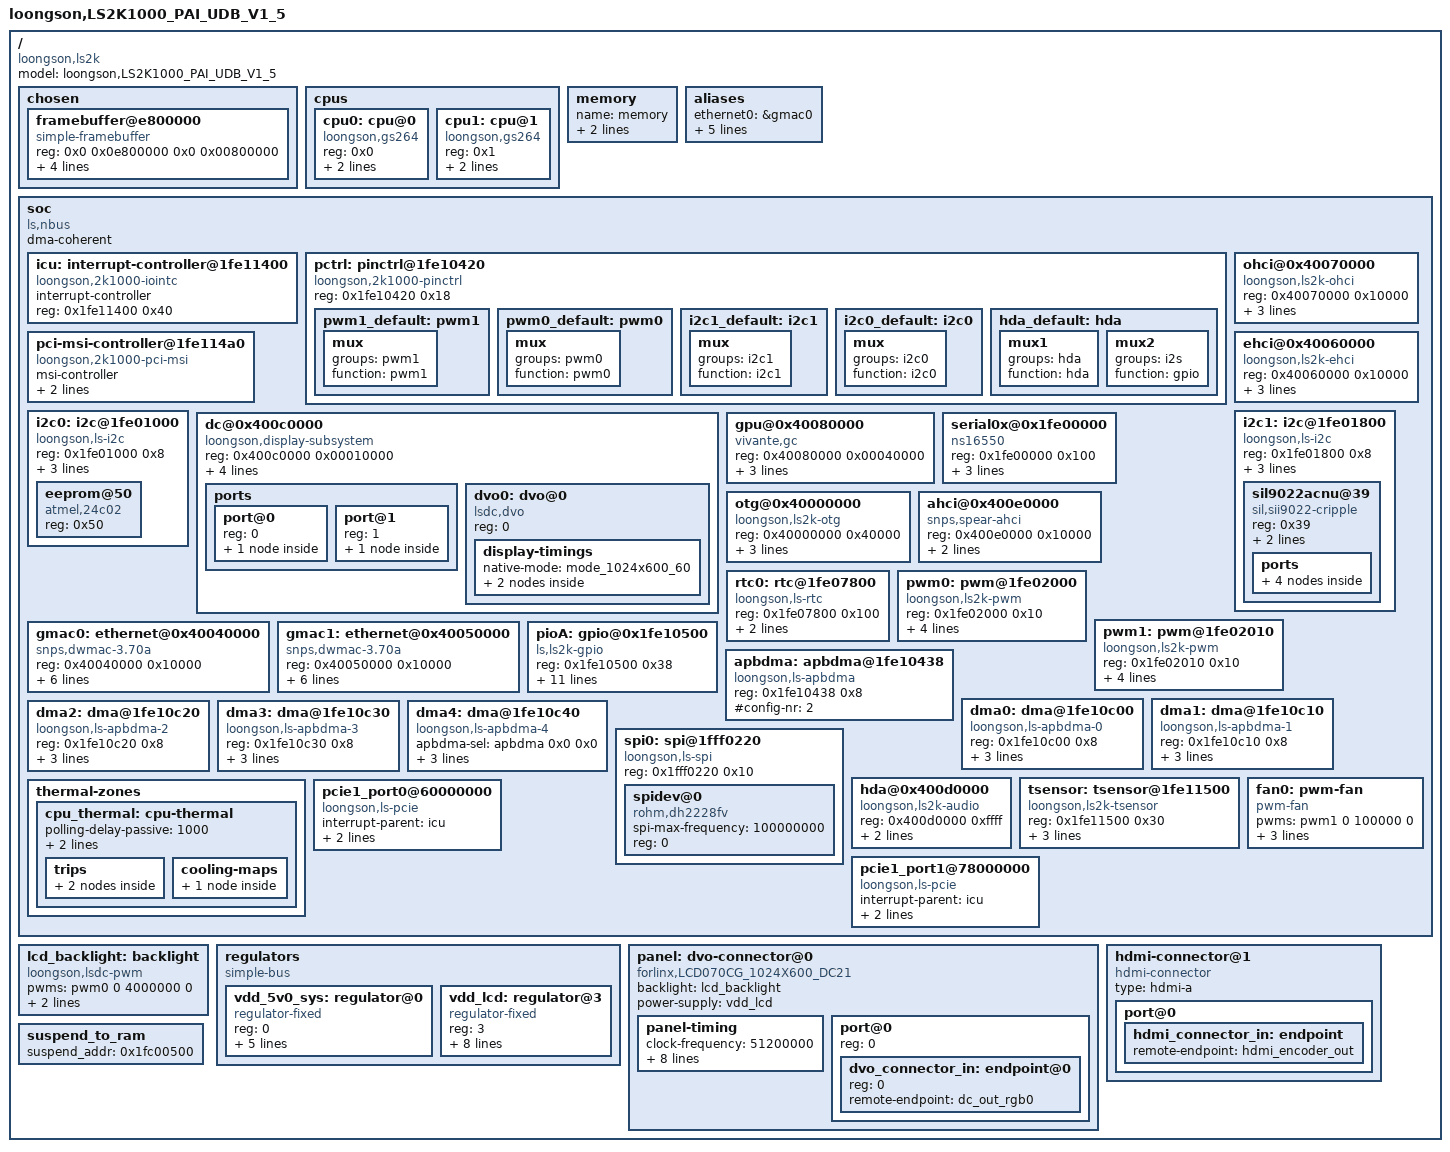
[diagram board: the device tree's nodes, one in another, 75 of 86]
/*
 * 2K1000 Device Tree Source for LS2K1000 boards
 */

#include <dt-bindings/thermal/thermal.h>
#include <dt-bindings/gpio/gpio.h>
#include <dt-bindings/pwm/pwm.h>

/dts-v1/;
/ {
	model = "loongson,LS2K1000_PAI_UDB_V1_5";
	compatible = "loongson,ls2k";
	#address-cells = <2>;
	#size-cells = <2>;

	/* This enables graphical output via bootloader-enabled display */
	chosen {
		// bootargs = "console=ttyS0,115200 root=/dev/sda1";

		#address-cells = <2>;
		#size-cells = <2>;
		ranges;

		framebuffer@e800000 {
			status= "okay";
			compatible = "simple-framebuffer";
			reg = <0x0 0x0e800000 0x0 0x00800000>;
			width = <1024>;
			height = <600>;
			stride = <(1024 * 2)>;
			format = "r5g6b5";
		};

		/*
		framebuffer@e800000 {
			status= "okay";
			compatible = "simple-framebuffer";
			reg = <0x0 0x0e800000 0x0 0x00800000>;
			width = <800>;
			height = <480>;
			stride = <(800 * 2)>;
			format = "r5g6b5";
		};
		*/
	};

	cpus {
		#address-cells = <1>;
		#size-cells = <0>;

		cpu0: cpu@0 {
			device_type = "cpu";
			compatible = "loongson,gs264";
			reg = <0x0>;
			loongson,dvfs-vid-points = <
				/* Node:kHz  DVFS:vid[0:5] */
				266666  0x11
				320000  0x10
				400000  0x01
				533333  0x00
				800000  0x00
				>;
		};

		cpu1: cpu@1 {
			device_type = "cpu";
			compatible = "loongson,gs264";
			reg = <0x1>;
			loongson,dvfs-vid-points = <
				/* Node:kHz  DVFS:vid[0:5] */
				266666  0x11
				320000  0x10
				400000  0x01
				533333  0x11
				800000  0x11
				>;
		};
	};

	// ls2k1000 pai board have only 2GB on-board RAM
	memory {
		name = "memory";
		device_type = "memory";
		// 238 MB at 2 MB
		// 496 MB at 512 MB
		// 1280 MB at 4352 MB
		// total 2014 MB
		reg = <0x00000000 0x00200000 0x00000000 0x0ee00000
		       0x00000000 0x20000000 0x00000000 0x1f000000
		       0x00000000 0x90000000 0x00000000 0x50000000>;
	};

	aliases {
		ethernet0 = &gmac0;
		ethernet1 = &gmac1;
		i2c0 = &i2c0;
		i2c1 = &i2c1;
		pwm0 = &pwm0;
		pwm1 = &pwm1;
	};
	// all soc device use 32bit address

	soc {
		compatible = "ls,nbus", "simple-bus";
		#address-cells = <1>;
		#size-cells = <1>;
		ranges = <0x10000000 0 0x10000000 0x10000000
			  0x40000000 0 0x40000000 0x40000000
			  0x20000000 0 0x20000000 0x20000000
			  0x0d000000 0 0x0d000000 0x02000000>;

		dma-coherent;

		icu: interrupt-controller@1fe11400 {
			compatible = "loongson,2k1000-iointc";
			interrupt-controller;
			#interrupt-cells = <1>;
			reg = <0x1fe11400 0x40>;
		};

		pctrl:pinctrl@1fe10420 {
			compatible = "loongson,2k1000-pinctrl";
			reg = <0x1fe10420 0x18>;

			pwm1_default:pwm1 {
				mux {
					groups ="pwm1";
					function ="pwm1";
				};
			};

			pwm0_default:pwm0 {
				mux {
					groups ="pwm0";
					function ="pwm0";
				};
			};

			i2c1_default:i2c1 {
				mux {
					groups ="i2c1";
					function ="i2c1";
				};
			};

			i2c0_default:i2c0 {
				mux {
					groups ="i2c0";
					function ="i2c0";
				};
			};

			hda_default:hda {
				mux1 {
					groups ="hda";
					function ="hda";
				};

				mux2 {
					groups ="i2s";
					function ="gpio";
				};
			};
		};

		pci-msi-controller@1fe114a0 {
			compatible = "loongson,2k1000-pci-msi";
			msi-controller;
			msi-mask = <0xc0 0x40000c00>;
			reg = <0x1fe114a0 0x60>;
		};

		ohci@0x40070000 {
			compatible = "loongson,ls2k-ohci", "usb-ohci";
			reg = <0x40070000 0x10000>;
			interrupt-parent = <&icu>;
			interrupts = <59>;
			dma-mask = <0x0 0xffffffff>;
		};

		ehci@0x40060000 {
			compatible = "loongson,ls2k-ehci", "usb-ehci";
			reg = <0x40060000 0x10000>;
			interrupt-parent = <&icu>;
			interrupts = <58>;
			dma-mask = <0xffffffff 0xffffffff>;
		};

		i2c0: i2c@1fe01000 {
			compatible = "loongson,ls-i2c";
			reg = <0x1fe01000 0x8>;
			interrupt-parent = <&icu>;
			interrupts = <30>;

			pinctrl-0 = <&i2c0_default>;
			pinctrl-names = "default";

			#address-cells = <1>;
			#size-cells = <0>;

			eeprom@50 {
				compatible = "atmel,24c02";
				reg = <0x50>;
			};
		};

		i2c1: i2c@1fe01800 {
			compatible = "loongson,ls-i2c";
			reg = <0x1fe01800 0x8>;
			interrupt-parent = <&icu>;
			interrupts = <31>;

			#address-cells = <1>;
			#size-cells = <0>;

			pinctrl-0 = <&i2c1_default>;
			pinctrl-names = "default";

			sil9022acnu@39 {
				compatible = "sil,sii9022-cripple";
				/* Transmitter Programming Interface (TPI) address: 0x72 */
				reg = <0x39>;

				hpd-gpios = <&pioA 0 GPIO_ACTIVE_HIGH>;
				/* reset-gpios = <&pioA 39 GPIO_ACTIVE_LOW>; */
				interrupt-parent = <&pioA>;

				status = "okay";

				ports {
					#address-cells = <1>;
					#size-cells = <0>;

					port@0 {
						reg = <0>;

						hdmi_encoder_in: endpoint {
							remote-endpoint = <&dc_out_rgb1>;
						};
					};

					port@1 {
						reg = <1>;

						hdmi_encoder_out: endpoint {
							remote-endpoint = <&hdmi_connector_in>;
						};
					};
				};
			};

		};

		dc@0x400c0000 {
			compatible = "loongson,display-subsystem";
			reg = <0x400c0000 0x00010000>;
			interrupt-parent = <&icu>;
			interrupts = <36>;
			dma-mask = <0x00000000 0xffffffff>;

			output-ports = <&dvo0>;

			#address-cells = <1>;
			#size-cells = <0>;

			ports {
				#address-cells = <1>;
				#size-cells = <0>;

				port@0 {
					reg = <0>;
					dc_out_rgb0: endpoint {
						remote-endpoint = <&dvo_connector_in>;
					};
				};

				port@1 {
					reg = <1>;
					dc_out_rgb1: endpoint {
						remote-endpoint = <&hdmi_encoder_in>;
					};
				};
			};

			dvo0: dvo@0 {
				compatible = "lsdc,dvo";
				/* 0 for connector 0 (DVO0) */
				reg = <0>;

				display-timings {
					native-mode = <&mode_1024x600_60>;

					mode_1024x600_60: display-timing@0 {
						clock-frequency = <51200000>;
						hactive = <1024>;
						vactive = <600>;
						hsync-len = <4>;
						hfront-porch = <160>;
						hback-porch = <156>;
						vfront-porch = <11>;
						vback-porch = <23>;
						vsync-len = <1>;
					};

					mode_800x480_60: display-timing@1 {
						clock-frequency = <30066000>;
						hactive = <800>;
						vactive = <480>;
						hfront-porch = <50>;
						hback-porch = <70>;
						hsync-len = <50>;
						vback-porch = <0>;
						vfront-porch = <0>;
						vsync-len = <50>;
					};
				};
			};

		};

		gpu@0x40080000 {
			compatible = "vivante,gc";
			reg = <0x40080000 0x00040000>;
			interrupt-parent = <&icu>;
			interrupts = <37>;
			dma-mask = <0x00000000 0xffffffff>;
		};

		serial0x@0x1fe00000{
			device_type = "serial";
			compatible = "ns16550";
			reg = <0x1fe00000 0x100>;
			clock-frequency = <125000000>;
			interrupt-parent = <&icu>;
			interrupts = <8>;
		};

		otg@0x40000000 {
			compatible = "loongson,ls2k-otg";
			reg = <0x40000000 0x40000>;
			interrupt-parent = <&icu>;
			interrupts = <57>;
			dma-mask = <0x0 0xffffffff>;
		};

		ahci@0x400e0000{
			compatible = "snps,spear-ahci";
			reg = <0x400e0000 0x10000>;
			interrupt-parent = <&icu>;
			interrupts = <27>;
		};

		rtc0: rtc@1fe07800{
			compatible = "loongson,ls-rtc";
			reg = <0x1fe07800 0x100>;
			interrupt-parent = <&icu>;
			interrupts = <60>;
		};

		pwm0: pwm@1fe02000 {
			compatible = "loongson,ls2k-pwm";
			reg = <0x1fe02000 0x10>;
			clock-frequency = <125000000>;
			interrupt-parent = <&icu>;
			interrupts = <32>;
			#pwm-cells = <3>;
			pinctrl-0 = <&pwm0_default>;
			pinctrl-names = "default";
		};

		pwm1: pwm@1fe02010 {
			compatible = "loongson,ls2k-pwm";
			reg = <0x1fe02010 0x10>;
			clock-frequency = <125000000>;
			interrupt-parent = <&icu>;
			interrupts = <33>;
			#pwm-cells = <3>;
			pinctrl-0 = <&pwm1_default>;
			pinctrl-names = "default";
		};

		/* PWM controller nodes:
		 * If you want to use the "PWM" function,enable the "PWM"
		 * controller by configure general configuration register 0.
		 */
		/*
		pwm2: pwm@1fe02020{
			compatible = "loongson,ls2k-pwm";
			reg = <0x1fe02020 0x10>;
			clock-frequency = <125000000>;
			interrupt-parent = <&icu>;
			interrupts = <34>;
			#pwm-cells = <2>;
		};

		pwm3: pwm@1fe02030{
			compatible = "loongson,ls2k-pwm";
			reg = <0x1fe02030 0x10>;
			clock-frequency = <125000000>;
			interrupt-parent = <&icu>;
			interrupts = <35>;
			#pwm-cells = <2>;
		};*/

		gmac0: ethernet@0x40040000 {
			compatible = "snps,dwmac-3.70a", "ls,ls-gmac";
			reg = <0x40040000 0x10000>;
			interrupt-parent = <&icu>;
			interrupts = <20 21>;
			interrupt-names = "macirq", "eth_wake_irq";
			/* mac-address = [ 64 48 48 48 48 60  ]; */
			phy-mode = "rgmii";
			bus_id = <0x0>;
			phy_addr = <0xffffffff>;
			dma-mask = <0xffffffff 0xffffffff>;
		};

		gmac1: ethernet@0x40050000 {
			compatible = "snps,dwmac-3.70a", "ls,ls-gmac";
			reg = <0x40050000 0x10000>;
			interrupt-parent = <&icu>;
			interrupts = <22 23>;
			interrupt-names = "macirq", "eth_wake_irq";
			/* mac-address = [ 64 48 48 48 48 61  ]; */
			phy-mode = "rgmii";
			bus_id = <0x1>;
			phy_addr = <0xffffffff>;
			dma-mask = <0xffffffff 0xffffffff>;
		};

		pioA: gpio@0x1fe10500 {
			compatible = "ls,ls2k-gpio", "ls,ls-gpio";
			reg = <0x1fe10500 0x38>;
			ngpios = <64>;
			gpio-controller;
			#gpio-cells = <2>;
			gpio-ranges = <&pctrl 0 0 15>,
				      <&pctrl 16 16 15>,
				      <&pctrl 32 32 10>,
				      <&pctrl 44 44 20>;
			interrupt-parent = <&icu>;
			interrupts =
				<68>, <69>, <70>, <71>, <66>, <66>,
				<66>, <66>, <66>, <66>, <66>, <66>,
				<66>, <66>, <66>, <>,   <66>, <66>,
				<66>, <66>, <66>, <66>, <66>, <66>,
				<66>, <66>, <66>, <66>, <66>, <66>,
				<66>, <66>, <67>, <67>, <67>, <67>,
				<67>, <>,   <67>, <67>, <67>, <67>,
				<>,   <>,   <67>, <67>, <67>, <67>,
				<67>, <67>, <67>, <67>, <67>, <67>,
				<67>, <67>, <67>, <67>, <67>, <67>,
				<67>, <67>, <67>, <67>;
		};

		/* APB DMA controller nodes:
		 * apbdma node specify the commom property for dma node.
		 * the #config-nr must be 2,Used to provide APB sel region
		 * and APB DMA controler information.
		 */
		apbdma: apbdma@1fe10438{
			compatible = "loongson,ls-apbdma";
			reg = <0x1fe10438 0x8>;
			#config-nr = <2>;
		};
		/* DMA node should specify the apbdma-sel property using a
		 * phandle to the controller followed by number of APB sel
		 * region(max 9) and number of APB DMA controller(max 4).
		*/
		dma0: dma@1fe10c00 {
			compatible = "loongson,ls-apbdma-0";
			reg = <0x1fe10c00 0x8>;
			apbdma-sel = <&apbdma 0x0 0x0>;
			#dma-cells = <1>;
			dma-channels = <1>;
			dma-requests = <1>;
		};
		dma1: dma@1fe10c10 {
			compatible = "loongson,ls-apbdma-1";
			reg = <0x1fe10c10 0x8>;
			apbdma-sel = <&apbdma 0x5 0x1>;
			#dma-cells = <1>;
			dma-channels = <1>;
			dma-requests = <1>;
		};
		dma2: dma@1fe10c20 {
			compatible = "loongson,ls-apbdma-2";
			reg = <0x1fe10c20 0x8>;
			apbdma-sel = <&apbdma 0x6 0x2>;
			#dma-cells = <1>;
			dma-channels = <1>;
			dma-requests = <1>;
		};
		dma3: dma@1fe10c30 {
			compatible = "loongson,ls-apbdma-3";
			reg = <0x1fe10c30 0x8>;
			apbdma-sel = <&apbdma 0x7 0x3>;
			#dma-cells = <1>;
			dma-channels = <1>;
			dma-requests = <1>;
		};
		dma4: dma@1fe10c40 {
			compatible = "loongson,ls-apbdma-4";
			apbdma-sel = <&apbdma 0x0 0x0>;
			reg = <0x1fe10c40 0x8>;
			#dma-cells = <1>;
			dma-channels = <1>;
			dma-requests = <1>;
		};

		spi0: spi@1fff0220{
			compatible = "loongson,ls-spi";
			#address-cells = <1>;
			#size-cells = <0>;
			reg = <0x1fff0220 0x10>;
			spidev@0{
				compatible = "rohm,dh2228fv";
				spi-max-frequency = <100000000>;
				reg = <0>;
			};
		};


		hda@0x400d0000 {
			compatible = "loongson,ls2k-audio";
			reg = <0x400d0000 0xffff>;
			interrupt-parent = <&icu>;
			interrupts = <12>;
		};

		tsensor: tsensor@1fe11500 {
			compatible = "loongson,ls2k-tsensor";
			reg = <0x1fe11500 0x30>;
			id = <0>;
			interrupt-parent = <&icu>;
			interrupts = <15>;
			#thermal-sensor-cells = <1>;
		};

		fan0: pwm-fan {
			compatible = "pwm-fan";
			pwms = <&pwm1 0 100000 0>;
			cooling-min-state = <0>;
			cooling-max-state = <3>;
			#cooling-cells = <2>;
			cooling-levels = <0 102 170 230>;
		};

		thermal-zones {
			cpu_thermal: cpu-thermal {
				polling-delay-passive = <1000>;
				polling-delay = <5000>;
				thermal-sensors = <&tsensor 0>;

				trips {
					cpu_alert: cpu-alert {
						temperature = <60000>;
						hysteresis = <5000>;
						type = "active";
					};

					cpu_crit: cpu-crit {
						temperature = <85000>;
						hysteresis = <5000>;
						type = "critical";
					};
				};

				cooling-maps {
					map0 {
						trip = <&cpu_alert>;
						cooling-device =
							<&fan0 THERMAL_NO_LIMIT
							THERMAL_NO_LIMIT>;
					};
				};
			};
		};

		pcie1_port0@60000000 {
			compatible = "loongson,ls-pcie";
			interrupt-parent = <&icu>;
			interrupts = <44>;
			#address-cells = <3>;
			#size-cells = <2>;
			bus-range = <0x10 0x12>;
			ranges = <0x2000000 0x0 0x50000000 0x50000000 0x0 0x20000000 /* mem */
				  0x1000000 0x0 0x18004000 0x18004000 0x0 0x1000>;   /* io */
		};

		pcie1_port1@78000000 {
			compatible = "loongson,ls-pcie";
			interrupt-parent = <&icu>;
			interrupts = <45>;
			#address-cells = <3>;
			#size-cells = <2>;
			bus-range = <0x14 0x16>;
			ranges = <0x2000000 0x0 0x17f00000 0x17f00000 0x0 0x100000  /* mem */
				  0x1000000 0x0 0x19fff000 0x19fff000 0x0 0x1000>;  /* io */
		};

		/* CAN controller nodes:
		 * If you want to use the "can" function,enable the "can"
		 * controller by configure general configuration register 0.
		 */
		/*can0: can@1fe00c00{
			compatible = "nxp,sja1000";
			reg = <0x1fe00c00 0xff>;
			nxp,external-clock-frequency = <125000000>;
			interrupt-parent = <&icu>;
			interrupts = <24>;
		};
		can1: can@1fe00d00{
			compatible = "nxp,sja1000";
			reg = <0x1fe00d00 0xff>;
			nxp,external-clock-frequency = <125000000>;
			interrupt-parent = <&icu>;
			interrupts = <25>;
		};*/
	};

	lcd_backlight: backlight {
		compatible = "loongson,lsdc-pwm", "pwm-backlight";
		pwms = <&pwm0 0 4000000 0>;
		brightness-levels = <0 1 2 4 8 16 32 64 128 255>;
		default-brightness-level = <9>;
		status = "okay";
	};


	regulators {
		compatible = "simple-bus";
		#address-cells = <1>;
		#size-cells = <0>;

		vdd_5v0_sys: regulator@0 {
			compatible = "regulator-fixed";
			reg = <0>;
			regulator-name = "VDD_5V0_SYS";
			regulator-min-microvolt = <5000000>;
			regulator-max-microvolt = <5000000>;
			regulator-always-on;
			regulator-boot-on;
		};

		vdd_lcd: regulator@3 {
			compatible = "regulator-fixed";
			reg = <3>;
			regulator-name = "+VDD_LED";
			regulator-min-microvolt = <5000000>;
			regulator-max-microvolt = <5000000>;
			regulator-always-on;
			gpio = <&pioA 3 GPIO_ACTIVE_HIGH>;
			regulator-boot-on;
			enable-active-high;
			vin-supply = <&vdd_5v0_sys>;
		};
	};


	panel: dvo-connector@0 {
		/* 1024X600 */
		compatible = "forlinx,LCD070CG_1024X600_DC21", "hontron,070JIT2135-A2", "avic,tm070ddh03";
		/* 800x600 */
		/* compatible = "forlinx,hdw070tn93", "innolux,at070tn92"; */
		backlight = <&lcd_backlight>;

		/* lcd power on control gpio */
		/* enable-gpios = <&pioA 3 GPIO_ACTIVE_HIGH>; */

		power-supply = <&vdd_lcd>;

		status = "okay";

		#address-cells = <1>;
		#size-cells = <0>;

		panel-timing {
			clock-frequency = <51200000>;
			hactive = <1024>;
			vactive = <600>;
			hsync-len = <4>;
			hfront-porch = <160>;
			hback-porch = <156>;
			vfront-porch = <11>;
			vback-porch = <23>;
			vsync-len = <1>;
		};

		port@0 {
			reg = <0>;

			#address-cells = <1>;
			#size-cells = <0>;

			dvo_connector_in: endpoint@0 {
				reg = <0>;
				remote-endpoint = <&dc_out_rgb0>;
			};
		};
	};

	hdmi-connector@1 {
		compatible = "hdmi-connector";
		type = "hdmi-a";

		status = "okay";

		port@0 {
			hdmi_connector_in: endpoint {
				remote-endpoint = <&hdmi_encoder_out>;
			};
		};
	};

	suspend_to_ram {
			suspend_addr = <0x1fc00500>;
	};

};
